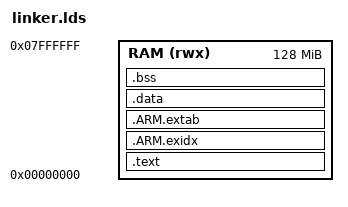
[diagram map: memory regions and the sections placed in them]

ENTRY(_start)

MEMORY
{
        RAM (rwx) : ORIGIN = 0x00000000, LENGTH = 128M
}

SECTIONS
{
        /**********************************************************************
         *                                                                    *
         **********************************************************************/
        .text :
        {
                _stext = .;
                KEEP(*(.vectors))
                *(.startup)
                *(.text)
                *(.text.*)
                *(.rodata)
                *(.rodata.*)
                . = ALIGN(4);
                PROVIDE(_debug_flag = .);
                BYTE(0x00);
                . = ALIGN(0x10);
/*
                __exidx_start = .;
                *(.ARM.exidx* .gnu.linkonce.armexidx.*)
                __exidx_end = .;
                *(.ARM.extab* .gnu.linkonce.armextab.*)
*/
                _etext = .;
        } > RAM
        /**********************************************************************
         *                                                                    *
         **********************************************************************/
        .ARM.exidx :
        {
                . = ALIGN(4);
                __exidx_start = .;
                *(.ARM.exidx*)
                . = ALIGN(4);
                __exidx_end = .;
        } > RAM
        .ARM.extab :
        {
                . = ALIGN(4);
                *(.ARM.extab*)
                . = ALIGN(4);
        } > RAM
        /**********************************************************************
         *                                                                    *
         **********************************************************************/
        .data :
        {
                _sdata = .;
                *(.data)
                *(.data.*)
                . = ALIGN(0x10);
                _edata = .;
        } > RAM
        /**********************************************************************
         *                                                                    *
         **********************************************************************/
        .bss ADDR(.data) + SIZEOF(.data) (NOLOAD) :
        {
                _sbss = .;
                *(.bss)
                *(.bss.*)
                *(COMMON)
                . = ALIGN(0x10);
                _ebss = .;
        } > RAM
        /**********************************************************************
         *                                                                    *
         **********************************************************************/
        .debug_info     0 : { *(.debug_info) }
        .debug_abbrev   0 : { *(.debug_abbrev) }
        .debug_aranges  0 : { obj/startup.o(.debug_aranges) *(.debug_aranges) }
        .debug_frame    0 : { *(.debug_frame) }
        .debug_line     0 : { *(.debug_line) }
        .debug_line_str 0 : { *(.debug_line_str) }
        .debug_loclists 0 : { *(.debug_loclists) }
        .debug_macro    0 : { *(.debug_macro) }
        .debug_names    0 : { *(.debug_names) }
        .debug_rnglists 0 : { *(.debug_rnglists) }
        .debug_str      0 : { *(.debug_str) }
        /**********************************************************************
         *                                                                    *
         **********************************************************************/
        /DISCARD/ :
        {
                *(*)
        }
}

